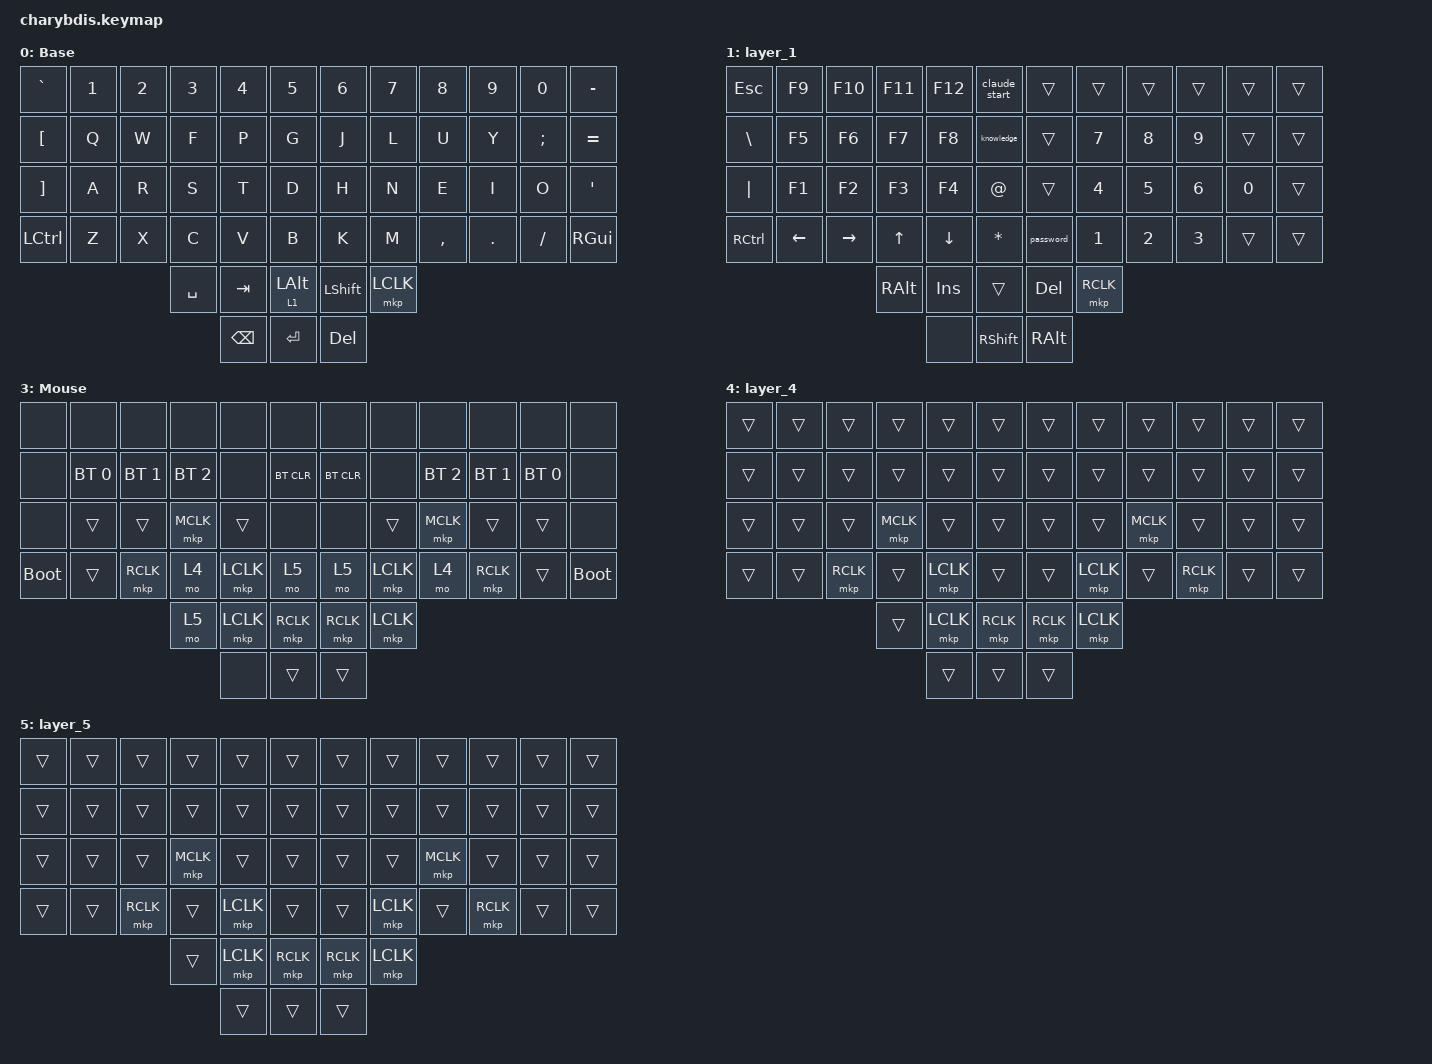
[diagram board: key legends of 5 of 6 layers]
#include <behaviors.dtsi>
#include <dt-bindings/zmk/bt.h>
#include <dt-bindings/zmk/keys.h>
#include <dt-bindings/zmk/mouse.h>

&lt {
    tapping-term-ms = <200>;
    flavor = "balanced";
    quick-tap-ms = <150>;
};

/ {
    combos {
        compatible = "zmk,combos";

        escc {
            bindings = <&kp ESC>;
            key-positions = <17 18>;
            layers = <0>;
        };
    };

    macros {
        password: password {
            compatible = "zmk,behavior-macro";
            #binding-cells = <0>;
            bindings = <&none &kp LS(P) &kp E &kp L &kp U &kp C &kp H &kp E &kp EXCL &kp N0 &kp N9 &kp N2 &kp N7>;
            label = "PASSWORD";
        };

        claude_start: claude_start {
            compatible = "zmk,behavior-macro";
            #binding-cells = <0>;
            bindings = <&none &kp C &kp L &kp A &kp U &kp D &kp E &kp SPACE &kp MINUS &kp MINUS &kp D &kp A &kp N &kp G &kp E &kp R &kp O &kp U &kp S &kp L &kp Y &kp MINUS &kp S &kp K &kp I &kp P &kp MINUS &kp P &kp E &kp R &kp M &kp I &kp S &none &kp S &kp I &kp O &kp N &kp S>;
            label = "CLAUDE_START";
            wait-ms = <10>;
        };

        knowledge: knowledge {
            compatible = "zmk,behavior-macro";
            #binding-cells = <0>;
            bindings = <&none &kp S &kp K &kp I &kp L &kp L &kp SPACE &kp K &kp N &kp O &kp W &kp L &kp E &kp D &kp G &kp E &kp MINUS &kp O &kp R &kp C &kp H &kp E &kp S &kp T &kp R &kp A &kp T &kp O &kp R>;
            label = "KNOWLEDGE";
            wait-ms = <5>;
        };
    };

    keymap {
        compatible = "zmk,keymap";
        Base {
            bindings = <
&kp GRAVE          &kp N1  &kp N2  &kp N3     &kp N4         &kp N5            &kp N6          &kp N7     &kp N8     &kp N9   &kp N0         &kp MINUS
&kp LEFT_BRACKET   &kp Q   &kp W   &kp F      &kp P          &kp G             &kp J           &kp L      &kp U      &kp Y    &kp SEMICOLON  &kp EQUAL
&kp RIGHT_BRACKET  &kp A   &kp R   &kp S      &kp T          &kp D             &kp H           &kp N      &kp E      &kp I    &kp O          &kp APOS
&kp LCTRL          &kp Z   &kp X   &kp C      &kp V          &kp B             &kp K           &kp M      &kp COMMA  &kp DOT  &kp SLASH      &kp RIGHT_GUI
                                   &kp SPACE  &kp TAB      &lt 1 LEFT_ALT    &kp LEFT_SHIFT  &mkp LCLK
                                              &kp BACKSPACE  &kp ENTER           &kp DELETE
            >;

            trackball-bindings = <&tmv_coarse>;
        };

        layer_1 {
            bindings = <
&kp ESCAPE     &kp F9          &kp F10          &kp F11       &kp F12         &claude_start          &trans         &trans        &trans        &trans        &trans        &trans
&kp BACKSLASH  &kp F5          &kp F6           &kp F7        &kp F8          &knowledge             &trans         &kp NUMBER_7  &kp NUMBER_8  &kp NUMBER_9  &trans        &trans
&kp PIPE       &kp F1          &kp F2           &kp F3        &kp F4          &kp AT_SIGN        &trans   &kp NUMBER_4  &kp NUMBER_5  &kp NUMBER_6  &kp NUMBER_0  &trans
&kp RCTRL      &kp LEFT_ARROW  &kp RIGHT_ARROW  &kp UP_ARROW  &kp DOWN_ARROW  &kp ASTERISK       &password      &kp NUMBER_1  &kp NUMBER_2  &kp NUMBER_3  &trans        &trans
                                                &kp RIGHT_ALT      &kp INS         &trans             &kp DELETE     &mkp RCLK
                                                              &none           &kp RIGHT_SHIFT    &kp RIGHT_ALT
            >;
        };

        layer_2 {
            bindings = <
&trans  &trans  &trans     &trans     &trans     &trans       &trans     &trans     &trans     &trans     &trans  &trans
&trans  &trans  &trans     &trans     &trans     &trans       &trans     &trans     &trans     &trans     &trans  &trans
&trans  &trans  &trans     &trans     &trans     &trans       &trans     &trans     &trans     &trans     &trans  &trans
                                          &trans   &trans      &trans       &trans        &trans
                                                         &trans         &trans          &none
            >;
        };

        Mouse {
            bindings = <
&none        &none         &none         &none         &none      &none         &none       &none      &none         &none         &none         &none
&none        &bt BT_SEL 0  &bt BT_SEL 1  &bt BT_SEL 2  &none      &bt BT_CLR    &bt BT_CLR  &none      &bt BT_SEL 2  &bt BT_SEL 1  &bt BT_SEL 0  &none
&none        &trans        &trans        &mkp MCLK     &trans     &none         &none       &trans     &mkp MCLK     &trans        &trans        &none
&bootloader  &trans        &mkp RCLK     &mo 4         &mkp LCLK  &mo 5         &mo 5       &mkp LCLK  &mo 4         &mkp RCLK     &trans        &bootloader
                                         &mo 5         &mkp LCLK  &mkp RCLK     &mkp RCLK   &mkp LCLK
                                                       &none      &trans        &trans
            >;
        };

        layer_4 {
            bindings = <
&trans  &trans  &trans     &trans     &trans     &trans       &trans     &trans     &trans     &trans     &trans  &trans
&trans  &trans  &trans     &trans     &trans     &trans       &trans     &trans     &trans     &trans     &trans  &trans
&trans  &trans  &trans     &mkp MCLK  &trans     &trans       &trans     &trans     &mkp MCLK  &trans     &trans  &trans
&trans  &trans  &mkp RCLK  &trans     &mkp LCLK  &trans       &trans     &mkp LCLK  &trans     &mkp RCLK  &trans  &trans
                           &trans     &mkp LCLK  &mkp RCLK    &mkp RCLK  &mkp LCLK
                                      &trans     &trans       &trans
            >;

            trackball-bindings = <&tsl>;//滚轮层
        };

        layer_5 {
            bindings = <
&trans  &trans  &trans     &trans     &trans     &trans       &trans     &trans     &trans     &trans     &trans  &trans
&trans  &trans  &trans     &trans     &trans     &trans       &trans     &trans     &trans     &trans     &trans  &trans
&trans  &trans  &trans     &mkp MCLK  &trans     &trans       &trans     &trans     &mkp MCLK  &trans     &trans  &trans
&trans  &trans  &mkp RCLK  &trans     &mkp LCLK  &trans       &trans     &mkp LCLK  &trans     &mkp RCLK  &trans  &trans
                           &trans     &mkp LCLK  &mkp RCLK    &mkp RCLK  &mkp LCLK
                                      &trans     &trans       &trans
            >;

            trackball-bindings = <&tmv_fine>;//精准指针层
        };
    };
};
